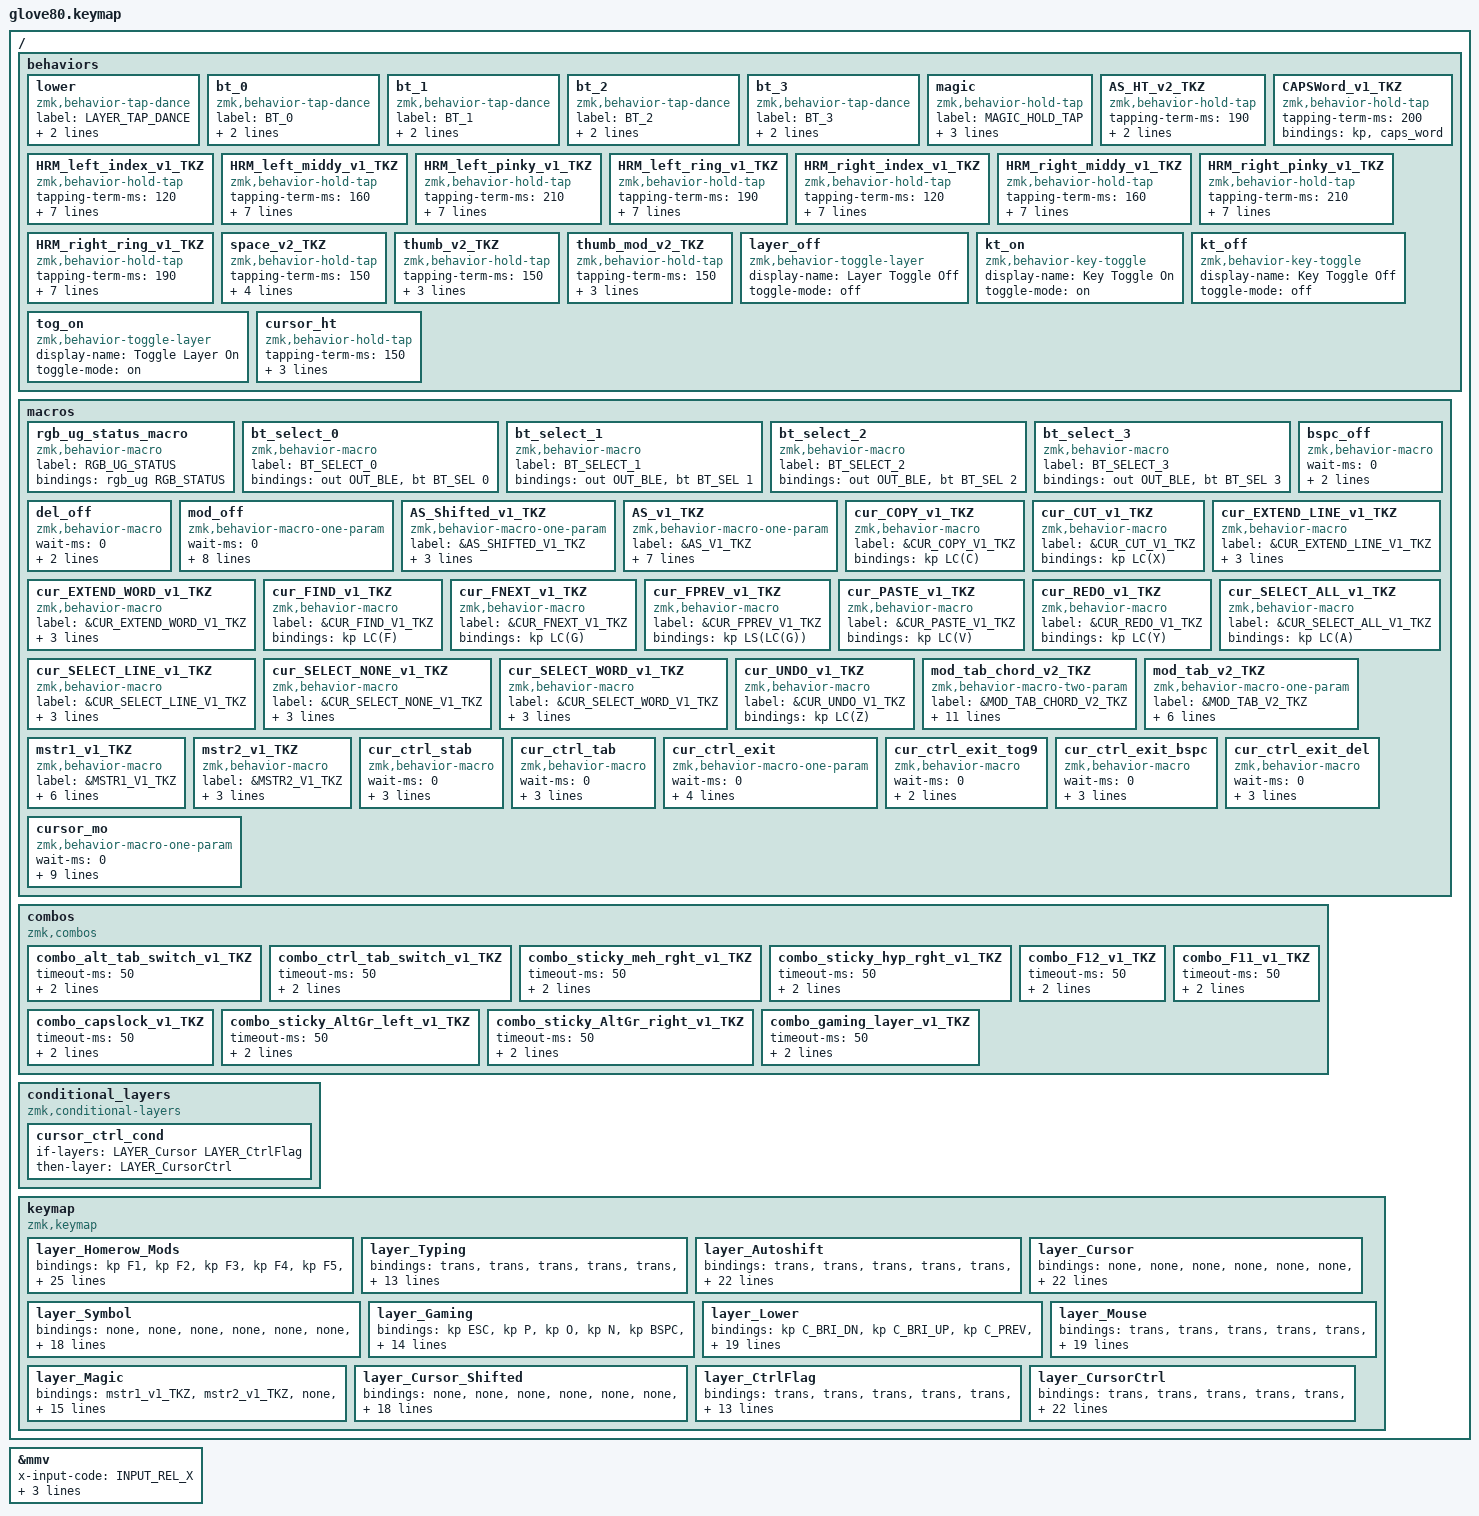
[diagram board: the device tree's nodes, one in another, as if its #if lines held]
/*
 * Copyright (c) 2020 The ZMK Contributors
 * Copyright (c) 2025 Innaworks Development Limited, trading as MoErgo
 *
 * SPDX-License-Identifier: MIT
 */


/* THIS FILE WAS GENERATED BY GLOVE80 LAYOUT EDITOR
 *
 * This file was generated automatically. You may or may not want to
 * edit it directly.
 */

#include <behaviors.dtsi>
/* Include all behavior includes needed */
#include <dt-bindings/zmk/outputs.h>
#include <dt-bindings/zmk/keys.h>
#include <dt-bindings/zmk/bt.h>
#include <dt-bindings/zmk/rgb.h>

/* On demand includes */
#define ZMK_POINTING_DEFAULT_MOVE_VAL 2100  // default: 600
#define ZMK_POINTING_DEFAULT_SCRL_VAL 20    // default: 10
#include <dt-bindings/zmk/pointing.h>

&mmv {
    x-input-code = <INPUT_REL_X>;
    y-input-code = <INPUT_REL_Y>;
    time-to-max-speed-ms = <700>;
    acceleration-exponent = <1>;
};

/* Automatically generated layer name #define */
#define LAYER_Homerow_Mods 0
#define LAYER_Typing 1
#define LAYER_Autoshift 2
#define LAYER_Cursor 3
#define LAYER_Symbol 4
#define LAYER_Gaming 5
#define LAYER_Lower 6
#define LAYER_Mouse 7
#define LAYER_Magic 8
#define LAYER_Cursor_Shifted 9
#define LAYER_CtrlFlag 10
#define LAYER_CursorCtrl 11

/* To deal with the situation where there is no Lower layer, to keep &lower happy */
#ifndef LAYER_Lower
#define LAYER_Lower 0
#endif

/* Custom Device-tree */


/* Input Listeners */


/* System behavior and Macros */
/ {
    behaviors {
        // For the "layer" key, it'd nice to be able to use it as either a shift or a toggle.
        // Configure it as a tap dance, so the first tap (or hold) is a &mo and the second tap is a &to
        lower: lower {
            compatible = "zmk,behavior-tap-dance";
            label = "LAYER_TAP_DANCE";
            #binding-cells = <0>;
            tapping-term-ms = <200>;
            bindings = <&mo LAYER_Lower>, <&to LAYER_Lower>;
        };
    };
};

/ {
    macros {
        rgb_ug_status_macro: rgb_ug_status_macro {
            label = "RGB_UG_STATUS";
            compatible = "zmk,behavior-macro";
            #binding-cells = <0>;
            bindings
                = <&rgb_ug RGB_STATUS>;
        };
    };
};


/ {
#ifdef BT_DISC_CMD
    behaviors {
        bt_0: bt_0 {
            compatible = "zmk,behavior-tap-dance";
            label = "BT_0";
            #binding-cells = <0>;
            tapping-term-ms = <200>;
            bindings = <&bt_select_0>, <&bt BT_DISC 0>;
        };
        bt_1: bt_1 {
            compatible = "zmk,behavior-tap-dance";
            label = "BT_1";
            #binding-cells = <0>;
            tapping-term-ms = <200>;
            bindings = <&bt_select_1>, <&bt BT_DISC 1>;
        };
        bt_2: bt_2 {
            compatible = "zmk,behavior-tap-dance";
            label = "BT_2";
            #binding-cells = <0>;
            tapping-term-ms = <200>;
            bindings = <&bt_select_2>, <&bt BT_DISC 2>;
        };
        bt_3: bt_3 {
            compatible = "zmk,behavior-tap-dance";
            label = "BT_3";
            #binding-cells = <0>;
            tapping-term-ms = <200>;
            bindings = <&bt_select_3>, <&bt BT_DISC 3>;
        };
    };
    macros {
        bt_select_0: bt_select_0 {
            label = "BT_SELECT_0";
            compatible = "zmk,behavior-macro";
            #binding-cells = <0>;
            bindings
                = <&out OUT_BLE>,
                  <&bt BT_SEL 0>;
        };
        bt_select_1: bt_select_1 {
            label = "BT_SELECT_1";
            compatible = "zmk,behavior-macro";
            #binding-cells = <0>;
            bindings
                = <&out OUT_BLE>,
                  <&bt BT_SEL 1>;
        };
        bt_select_2: bt_select_2 {
            label = "BT_SELECT_2";
            compatible = "zmk,behavior-macro";
            #binding-cells = <0>;
            bindings
                = <&out OUT_BLE>,
                  <&bt BT_SEL 2>;
        };
        bt_select_3: bt_select_3 {
            label = "BT_SELECT_3";
            compatible = "zmk,behavior-macro";
            #binding-cells = <0>;
            bindings
                = <&out OUT_BLE>,
                  <&bt BT_SEL 3>;
        };
    };
#else
    macros {
        bt_0: bt_0 {
            label = "BT_0";
            compatible = "zmk,behavior-macro";
            #binding-cells = <0>;
            bindings
                = <&out OUT_BLE>,
                  <&bt BT_SEL 0>;
        };
        bt_1: bt_1 {
            label = "BT_1";
            compatible = "zmk,behavior-macro";
            #binding-cells = <0>;
            bindings
                = <&out OUT_BLE>,
                  <&bt BT_SEL 1>;
        };
        bt_2: bt_2 {
            label = "BT_2";
            compatible = "zmk,behavior-macro";
            #binding-cells = <0>;
            bindings
                = <&out OUT_BLE>,
                  <&bt BT_SEL 2>;
        };
        bt_3: bt_3 {
            label = "BT_3";
            compatible = "zmk,behavior-macro";
            #binding-cells = <0>;
            bindings
                = <&out OUT_BLE>,
                  <&bt BT_SEL 3>;
        };
    };
#endif
};

/ {
    behaviors {
        magic: magic {
            compatible = "zmk,behavior-hold-tap";
            label = "MAGIC_HOLD_TAP";
            #binding-cells = <2>;
            flavor = "tap-preferred";
            tapping-term-ms = <200>;
            bindings = <&mo>, <&rgb_ug_status_macro>;
        };
    };
};

/* #define for key positions */
#define POS_LH_T1 52
#define POS_LH_T2 53
#define POS_LH_T3 54
#define POS_LH_T4 69
#define POS_LH_T5 70
#define POS_LH_T6 71
#define POS_LH_C1R2 15
#define POS_LH_C1R3 27
#define POS_LH_C1R4 39
#define POS_LH_C1R5 51
#define POS_LH_C2R1 4
#define POS_LH_C2R2 14
#define POS_LH_C2R3 26
#define POS_LH_C2R4 38
#define POS_LH_C2R5 50
#define POS_LH_C2R6 68
#define POS_LH_C3R1 3
#define POS_LH_C3R2 13
#define POS_LH_C3R3 25
#define POS_LH_C3R4 37
#define POS_LH_C3R5 49
#define POS_LH_C3R6 67
#define POS_LH_C4R1 2
#define POS_LH_C4R2 12
#define POS_LH_C4R3 24
#define POS_LH_C4R4 36
#define POS_LH_C4R5 48
#define POS_LH_C4R6 66
#define POS_LH_C5R1 1
#define POS_LH_C5R2 11
#define POS_LH_C5R3 23
#define POS_LH_C5R4 35
#define POS_LH_C5R5 47
#define POS_LH_C5R6 65
#define POS_LH_C6R1 0
#define POS_LH_C6R2 10
#define POS_LH_C6R3 22
#define POS_LH_C6R4 34
#define POS_LH_C6R5 46
#define POS_LH_C6R6 64
#define POS_RH_T1 57
#define POS_RH_T2 56
#define POS_RH_T3 55
#define POS_RH_T4 74
#define POS_RH_T5 73
#define POS_RH_T6 72
#define POS_RH_C1R2 16
#define POS_RH_C1R3 28
#define POS_RH_C1R4 40
#define POS_RH_C1R5 58
#define POS_RH_C2R1 5
#define POS_RH_C2R2 17
#define POS_RH_C2R3 29
#define POS_RH_C2R4 41
#define POS_RH_C2R5 59
#define POS_RH_C2R6 75
#define POS_RH_C3R1 6
#define POS_RH_C3R2 18
#define POS_RH_C3R3 30
#define POS_RH_C3R4 42
#define POS_RH_C3R5 60
#define POS_RH_C3R6 76
#define POS_RH_C4R1 7
#define POS_RH_C4R2 19
#define POS_RH_C4R3 31
#define POS_RH_C4R4 43
#define POS_RH_C4R5 61
#define POS_RH_C4R6 77
#define POS_RH_C5R1 8
#define POS_RH_C5R2 20
#define POS_RH_C5R3 32
#define POS_RH_C5R4 44
#define POS_RH_C5R5 62
#define POS_RH_C5R6 78
#define POS_RH_C6R1 9
#define POS_RH_C6R2 21
#define POS_RH_C6R3 33
#define POS_RH_C6R4 45
#define POS_RH_C6R5 63
#define POS_RH_C6R6 79

/* Custom Defined Behaviors */
/ {


};

/* Automatically generated macro definitions */
/ {
    macros {

        bspc_off: bspc_off {
            compatible = "zmk,behavior-macro";
            wait-ms = <0>;
            #binding-cells = <0>;
            bindings = <&layer_off LAYER_Cursor_Shifted>, <&kp BSPC>;
        };

        del_off: del_off {
            compatible = "zmk,behavior-macro";
            wait-ms = <0>;
            #binding-cells = <0>;
            bindings = <&layer_off LAYER_Cursor_Shifted>, <&kp DEL>;
        };

        mod_off: mod_off {
            compatible = "zmk,behavior-macro-one-param";
            wait-ms = <0>;
            tap-ms = <0>;
            #binding-cells = <1>;
            bindings = <&macro_tap &layer_off LAYER_Cursor_Shifted>,
            <&macro_param_1to1>,
            <&macro_press &mo MACRO_PLACEHOLDER>,
            <&macro_pause_for_release>,
            <&macro_param_1to1>,
            <&macro_release &mo MACRO_PLACEHOLDER>,
            <&macro_tap &layer_off LAYER_Cursor_Shifted>;
        };


        // AutoShift Helper- &AS main macro is chained to &AS_HT hold tap and &AS_Shifted macro - TailorKey
        AS_Shifted_v1_TKZ: AS_Shifted_v1_TKZ {
            label = "&AS_SHIFTED_V1_TKZ";
            compatible = "zmk,behavior-macro-one-param";
            #binding-cells = <1>;
            bindings = <&macro_press>
                , <&kp LSHFT>
                , <&macro_tap>
                , <&macro_param_1to1>
                , <&kp N1>
                , <&macro_release>
                , <&kp LSHFT>;
        };

        // AutoShift (Assign &AS to a Key) - &AS main macro is chained to &AS_HT hold tap and &AS_Shifted macro - TailorKey
        AS_v1_TKZ: AS_v1_TKZ {
            label = "&AS_V1_TKZ";
            compatible = "zmk,behavior-macro-one-param";
            #binding-cells = <1>;
            tap-ms = <10>;
            wait-ms = <10>;
            bindings = <&macro_press>
                , <&macro_param_1to1>
                , <&macro_param_1to2>
                , <&AS_HT_v2_TKZ A A>
                , <&macro_pause_for_release>
                , <&macro_release>
                , <&macro_param_1to1>
                , <&macro_param_1to2>
                , <&AS_HT_v2_TKZ A A>;
        };

        // Cursor Layer - Copy (Ctrl C) - TailorKey
        cur_COPY_v1_TKZ: cur_COPY_v1_TKZ {
            label = "&CUR_COPY_V1_TKZ";
            compatible = "zmk,behavior-macro";
            #binding-cells = <0>;
            bindings = <&kp LC(C)>;
        };

        // Cursor Layer - Cut (Ctrl X) - TailorKey
        cur_CUT_v1_TKZ: cur_CUT_v1_TKZ {
            label = "&CUR_CUT_V1_TKZ";
            compatible = "zmk,behavior-macro";
            #binding-cells = <0>;
            bindings = <&kp LC(X)>;
        };

        // Cursor Layer - Extent Line (seq) - TailorKey
        cur_EXTEND_LINE_v1_TKZ: cur_EXTEND_LINE_v1_TKZ {
            label = "&CUR_EXTEND_LINE_V1_TKZ";
            compatible = "zmk,behavior-macro";
            #binding-cells = <0>;
            tap-ms = <1>;
            wait-ms = <1>;
            bindings = <&kp LS(END)>;
        };

        // Cursor Layer - Extend Word (seq) - TailorKey
        cur_EXTEND_WORD_v1_TKZ: cur_EXTEND_WORD_v1_TKZ {
            label = "&CUR_EXTEND_WORD_V1_TKZ";
            compatible = "zmk,behavior-macro";
            #binding-cells = <0>;
            tap-ms = <1>;
            wait-ms = <1>;
            bindings = <&kp LC(LS(RIGHT))>;
        };

        // Cursor Layer - Find (Ctrl F) - TailorKey
        cur_FIND_v1_TKZ: cur_FIND_v1_TKZ {
            label = "&CUR_FIND_V1_TKZ";
            compatible = "zmk,behavior-macro";
            #binding-cells = <0>;
            bindings = <&kp LC(F)>;
        };

        // Cursor Layer - Find Next (Ctrl G) - TailorKey
        cur_FNEXT_v1_TKZ: cur_FNEXT_v1_TKZ {
            label = "&CUR_FNEXT_V1_TKZ";
            compatible = "zmk,behavior-macro";
            #binding-cells = <0>;
            bindings = <&kp LC(G)>;
        };

        // Cursor Layer - Find Prev (Ctrl Shift G) - TailorKey
        cur_FPREV_v1_TKZ: cur_FPREV_v1_TKZ {
            label = "&CUR_FPREV_V1_TKZ";
            compatible = "zmk,behavior-macro";
            #binding-cells = <0>;
            bindings = <&kp LS(LC(G))>;
        };

        // Cursor Layer - Paste (Ctrl V) - TailorKey
        cur_PASTE_v1_TKZ: cur_PASTE_v1_TKZ {
            label = "&CUR_PASTE_V1_TKZ";
            compatible = "zmk,behavior-macro";
            #binding-cells = <0>;
            bindings = <&kp LC(V)>;
        };

        // Cursor Layer - Redo (Ctrl Y) - TailorKey
        cur_REDO_v1_TKZ: cur_REDO_v1_TKZ {
            label = "&CUR_REDO_V1_TKZ";
            compatible = "zmk,behavior-macro";
            #binding-cells = <0>;
            bindings = <&kp LC(Y)>;
        };

        // Cursor Layer - Selest All (Ctrl A) - TailorKey
        cur_SELECT_ALL_v1_TKZ: cur_SELECT_ALL_v1_TKZ {
            label = "&CUR_SELECT_ALL_V1_TKZ";
            compatible = "zmk,behavior-macro";
            #binding-cells = <0>;
            bindings = <&kp LC(A)>;
        };

        // Cursor Layer - Select Line (seq) - TailorKey
        cur_SELECT_LINE_v1_TKZ: cur_SELECT_LINE_v1_TKZ {
            label = "&CUR_SELECT_LINE_V1_TKZ";
            compatible = "zmk,behavior-macro";
            #binding-cells = <0>;
            tap-ms = <1>;
            wait-ms = <1>;
            bindings = <&kp HOME>
                , <&kp LS(END)>;
        };

        // Cursor Layer - Select None (seq) - TailorKey
        cur_SELECT_NONE_v1_TKZ: cur_SELECT_NONE_v1_TKZ {
            label = "&CUR_SELECT_NONE_V1_TKZ";
            compatible = "zmk,behavior-macro";
            #binding-cells = <0>;
            tap-ms = <1>;
            wait-ms = <1>;
            bindings = <&kp DOWN>
                , <&kp UP>
                , <&kp RIGHT>
                , <&kp LEFT>;
        };

        // Cursor Layer - Select Word (seq) - TailorKey
        cur_SELECT_WORD_v1_TKZ: cur_SELECT_WORD_v1_TKZ {
            label = "&CUR_SELECT_WORD_V1_TKZ";
            compatible = "zmk,behavior-macro";
            #binding-cells = <0>;
            tap-ms = <1>;
            wait-ms = <1>;
            bindings = <&kp LC(LEFT)>
                , <&kp LC(LS(RIGHT))>;
        };

        // Cursor Layer - Undo (Ctrl Z) - TailorKey
        cur_UNDO_v1_TKZ: cur_UNDO_v1_TKZ {
            label = "&CUR_UNDO_V1_TKZ";
            compatible = "zmk,behavior-macro";
            #binding-cells = <0>;
            bindings = <&kp LC(Z)>;
        };

        // mod_tab_switcher_chord -  TailorKey
        mod_tab_chord_v2_TKZ: mod_tab_chord_v2_TKZ {
            label = "&MOD_TAB_CHORD_V2_TKZ";
            compatible = "zmk,behavior-macro-two-param";
            #binding-cells = <2>;
            tap-ms = <0>;
            wait-ms = <0>;
            bindings = <&macro_press>
                , <&macro_param_2to1>
                , <&mo MACRO_PLACEHOLDER>
                , <&macro_press>
                , <&macro_param_1to1>
                , <&mod_tab_v2_TKZ MACRO_PLACEHOLDER>
                , <&macro_pause_for_release>
                , <&macro_release>
                , <&macro_param_1to1>
                , <&mod_tab_v2_TKZ MACRO_PLACEHOLDER>
                , <&macro_release>
                , <&macro_param_2to1>
                , <&mo MACRO_PLACEHOLDER>;
        };

        // mod_tab_switcher - TailorKey
        //
        //
        mod_tab_v2_TKZ: mod_tab_v2_TKZ {
            label = "&MOD_TAB_V2_TKZ";
            compatible = "zmk,behavior-macro-one-param";
            #binding-cells = <1>;
            tap-ms = <0>;
            wait-ms = <0>;
            bindings = <&macro_press>
                , <&macro_param_1to1>
                , <&kp MACRO_PLACEHOLDER>
                , <&macro_tap>
                , <&kp TAB>
                , <&macro_pause_for_release>
                , <&macro_release>
                , <&macro_param_1to1>
                , <&kp MACRO_PLACEHOLDER>;
        };

        // macro string1 sample - Magic Layer F1 - Text output sample macro 1 "¡Hola!" - TailorKey
        mstr1_v1_TKZ: mstr1_v1_TKZ {
            label = "&MSTR1_V1_TKZ";
            compatible = "zmk,behavior-macro";
            #binding-cells = <0>;
            bindings = <&macro_press>
                , <&kp RALT>
                , <&macro_tap>
                , <&kp KP_N0>
                , <&kp KP_N1>
                , <&kp KP_N6>
                , <&kp KP_N1>
                , <&macro_release>
                , <&kp RALT>
                , <&macro_press>
                , <&kp LSHFT>
                , <&macro_tap>
                , <&kp H>
                , <&macro_release>
                , <&kp LSHFT>
                , <&macro_tap>
                , <&kp O>
                , <&kp L>
                , <&kp A>
                , <&kp EXCL>
                , <&kp SPACE>
                , <&kp RET>;
        };

        // macro string2 sample - Magic Layer F2 - Text output sample macro 2 "grammar check: <paste>" - TailorKey
        mstr2_v1_TKZ: mstr2_v1_TKZ {
            label = "&MSTR2_V1_TKZ";
            compatible = "zmk,behavior-macro";
            #binding-cells = <0>;
            bindings = <&macro_tap>
                , <&kp G>
                , <&kp R>
                , <&kp A>
                , <&kp M>
                , <&kp M>
                , <&kp A>
                , <&kp R>
                , <&kp SPACE>
                , <&kp C>
                , <&kp H>
                , <&kp E>
                , <&kp C>
                , <&kp K>
                , <&kp COLON>
                , <&kp LC(V)>
                , <&kp RET>;
        };

        cur_ctrl_stab: cur_ctrl_stab {
            compatible = "zmk,behavior-macro";
            wait-ms = <0>;
            tap-ms = <0>;
            #binding-cells = <0>;
            bindings = <&kt_on LCTRL>, <&tog_on LAYER_CtrlFlag>, <&kp LS(TAB)>;
        };

        cur_ctrl_tab: cur_ctrl_tab {
            compatible = "zmk,behavior-macro";
            wait-ms = <0>;
            tap-ms = <0>;
            #binding-cells = <0>;
            bindings = <&kt_on LCTRL>, <&tog_on LAYER_CtrlFlag>, <&kp TAB>;
        };

        cur_ctrl_exit: cur_ctrl_exit {
            compatible = "zmk,behavior-macro-one-param";
            wait-ms = <0>;
            tap-ms = <0>;
            #binding-cells = <1>;
            bindings = <&kt_off LCTRL>,
                       <&layer_off LAYER_CtrlFlag>,
                       <&macro_param_1to1>,
                       <&kp MACRO_PLACEHOLDER>;
        };

        cur_ctrl_exit_tog9: cur_ctrl_exit_tog9 {
            compatible = "zmk,behavior-macro";
            wait-ms = <0>;
            #binding-cells = <0>;
            bindings = <&kt_off LCTRL>, <&layer_off LAYER_CtrlFlag>, <&tog 9>;
        };

        cur_ctrl_exit_bspc: cur_ctrl_exit_bspc {
            compatible = "zmk,behavior-macro";
            wait-ms = <0>;
            #binding-cells = <0>;
            bindings = <&kt_off LCTRL>, <&layer_off LAYER_CtrlFlag>, <&layer_off LAYER_Cursor_Shifted>, <&kp BSPC>;
        };

        cur_ctrl_exit_del: cur_ctrl_exit_del {
            compatible = "zmk,behavior-macro";
            wait-ms = <0>;
            #binding-cells = <0>;
            bindings = <&kt_off LCTRL>, <&layer_off LAYER_CtrlFlag>, <&layer_off LAYER_Cursor_Shifted>, <&kp DEL>;
        };

        cursor_mo: cursor_mo {
            compatible = "zmk,behavior-macro-one-param";
            wait-ms = <0>;
            tap-ms = <0>;
            #binding-cells = <1>;
            bindings = <&macro_tap &layer_off LAYER_Cursor_Shifted>,
                       <&macro_param_1to1>,
                       <&macro_press &mo MACRO_PLACEHOLDER>,
                       <&macro_pause_for_release>,
                       <&kt_off LCTRL>,
                       <&layer_off LAYER_CtrlFlag>,
                       <&macro_param_1to1>,
                       <&macro_release &mo MACRO_PLACEHOLDER>,
                       <&macro_tap &layer_off LAYER_Cursor_Shifted>;
        };
    };
};

/* Automatically generated behavior definitions */
/ {
    behaviors {

        // AutoShift Helper - &AS main macro is chained to &AS_HT hold tap and &AS_Shifted macro. For faster typists, it is recommended to decrease the tapping-term-ms value. A suggested value is 135 ms.
        // More: https://github.com/nickcoutsos/keymap-editor/wiki/Autoshift-using-ZMK-behaviors
        AS_HT_v2_TKZ: AS_HT_v2_TKZ {
            compatible = "zmk,behavior-hold-tap";
            #binding-cells = <2>;
            tapping-term-ms = <190>;
            bindings = <&AS_Shifted_v1_TKZ>, <&kp>;
            flavor = "tap-preferred";
        };

        // Capsword helper - tap for caps_word - hold for key press
        CAPSWord_v1_TKZ: CAPSWord_v1_TKZ {
            compatible = "zmk,behavior-hold-tap";
            #binding-cells = <2>;
            tapping-term-ms = <200>;
            bindings = <&kp>, <&caps_word>;
        };

        // Homerow Mod for the left index finger - TailorKey.
        // For advanced tuning of HRM values, see: https://docs.google.com/spreadsheets/d/1ESgObQelyz4lnKlfwLYsmofLJulOMK5RdGBsopLe2o8
        HRM_left_index_v1_TKZ: HRM_left_index_v1_TKZ {
            compatible = "zmk,behavior-hold-tap";
            #binding-cells = <2>;
            tapping-term-ms = <120>;
            bindings = <&kp>, <&kp>;
            flavor = "tap-preferred";
            quick-tap-ms = <250>;
            require-prior-idle-ms = <50>;
            hold-trigger-key-positions = <57 56 55 72 73 74 5 6 7 8 16 17 18 19 20 28 29 30 31 32 40 41 42 43 44 58 59 60 61 62 75 76 77 78 9 21 33 45 63 79 52 53 54 70 71 69>;
            hold-trigger-on-release;
        };

        // Homerow Mod for the left middle finger - TailorKey
        HRM_left_middy_v1_TKZ: HRM_left_middy_v1_TKZ {
            compatible = "zmk,behavior-hold-tap";
            #binding-cells = <2>;
            tapping-term-ms = <160>;
            bindings = <&kp>, <&kp>;
            flavor = "tap-preferred";
            quick-tap-ms = <250>;
            require-prior-idle-ms = <100>;
            hold-trigger-key-positions = <57 56 55 72 73 74 5 6 7 8 16 17 18 19 20 28 29 30 31 32 40 41 42 43 44 58 59 60 61 62 75 76 77 78 9 21 33 45 63 79 52 53 54 69 70 71>;
            hold-trigger-on-release;
        };

        // Homerow Mod for the left pinky - TailorKey
        HRM_left_pinky_v1_TKZ: HRM_left_pinky_v1_TKZ {
            compatible = "zmk,behavior-hold-tap";
            #binding-cells = <2>;
            tapping-term-ms = <210>;
            bindings = <&kp>, <&kp>;
            flavor = "tap-preferred";
            quick-tap-ms = <250>;
            require-prior-idle-ms = <100>;
            hold-trigger-key-positions = <57 56 55 72 73 74 5 6 7 8 9 16 17 18 19 20 21 29 30 31 32 33 42 43 44 45 60 61 62 63 28 40 41 58 59 75 76 77 79 78 52 53 54 69 70 71>;
            hold-trigger-on-release;
        };

        // Homerow Mod for the left ring finger 1 - TailorKey
        HRM_left_ring_v1_TKZ: HRM_left_ring_v1_TKZ {
            compatible = "zmk,behavior-hold-tap";
            #binding-cells = <2>;
            tapping-term-ms = <190>;
            bindings = <&kp>, <&kp>;
            flavor = "tap-preferred";
            quick-tap-ms = <250>;
            require-prior-idle-ms = <100>;
            hold-trigger-key-positions = <57 56 55 72 73 74 5 6 7 8 16 17 18 19 20 28 29 30 31 32 40 41 42 43 44 58 59 60 61 62 75 76 77 78 9 21 33 45 63 79 52 53 54 69 70 71>;
            hold-trigger-on-release;
        };

        // Homerow Mod for the right index finger - TailorKey
        HRM_right_index_v1_TKZ: HRM_right_index_v1_TKZ {
            compatible = "zmk,behavior-hold-tap";
            #binding-cells = <2>;
            tapping-term-ms = <120>;
            bindings = <&kp>, <&kp>;
            flavor = "tap-preferred";
            quick-tap-ms = <250>;
            require-prior-idle-ms = <50>;
            hold-trigger-key-positions = <52 53 54 71 70 69 0 1 10 11 12 13 14 22 23 24 25 26 27 34 35 36 37 38 39 46 47 48 49 50 51 64 65 66 67 68 15 4 2 3 55 56 57 72 73 74>;
            hold-trigger-on-release;
        };

        // Homerow Mod for the right middle finger - TailorKey
        HRM_right_middy_v1_TKZ: HRM_right_middy_v1_TKZ {
            compatible = "zmk,behavior-hold-tap";
            #binding-cells = <2>;
            tapping-term-ms = <160>;
            bindings = <&kp>, <&kp>;
            flavor = "tap-preferred";
            quick-tap-ms = <250>;
            require-prior-idle-ms = <100>;
            hold-trigger-key-positions = <52 53 54 71 70 69 0 1 10 11 12 13 14 22 23 24 25 26 27 34 35 36 37 38 39 46 47 48 49 50 51 64 65 66 67 68 15 4 2 3 55 56 57 72 73 74>;
            hold-trigger-on-release;
        };

        // Homerow Mod for the right pinky - TailorKey
        HRM_right_pinky_v1_TKZ: HRM_right_pinky_v1_TKZ {
            compatible = "zmk,behavior-hold-tap";
            #binding-cells = <2>;
            tapping-term-ms = <210>;
            bindings = <&kp>, <&kp>;
            flavor = "tap-preferred";
            quick-tap-ms = <250>;
            require-prior-idle-ms = <100>;
            hold-trigger-key-positions = <52 53 54 71 70 69 0 1 10 11 12 13 14 22 23 24 25 26 27 34 35 36 37 38 39 46 47 48 49 50 51 64 65 66 67 68 15 4 2 3 55 56 57 72 73 74>;
            hold-trigger-on-release;
        };

        // Homerow Mod for the right ring 1 - TailorKey
        //
        HRM_right_ring_v1_TKZ: HRM_right_ring_v1_TKZ {
            compatible = "zmk,behavior-hold-tap";
            #binding-cells = <2>;
            tapping-term-ms = <190>;
            bindings = <&kp>, <&kp>;
            flavor = "tap-preferred";
            quick-tap-ms = <250>;
            require-prior-idle-ms = <100>;
            hold-trigger-key-positions = <52 53 54 71 70 69 0 1 10 11 12 13 14 22 23 24 25 26 27 34 35 36 37 38 39 46 47 48 49 50 51 64 65 66 67 68 15 4 2 3 55 56 57 72 73 74>;
            hold-trigger-on-release;
        };

        // space_layer_access - TailorKey
        space_v2_TKZ: space_v2_TKZ {
            compatible = "zmk,behavior-hold-tap";
            #binding-cells = <2>;
            tapping-term-ms = <150>;
            bindings = <&mo>, <&kp>;
            flavor = "balanced";
            quick-tap-ms = <100>;
            retro-tap;
        };

        // thumb_layer_access - TailorKey
        thumb_v2_TKZ: thumb_v2_TKZ {
            compatible = "zmk,behavior-hold-tap";
            #binding-cells = <2>;
            tapping-term-ms = <150>;
            bindings = <&mo>, <&kp>;
            flavor = "balanced";
            quick-tap-ms = <250>;
        };

        thumb_mod_v2_TKZ: thumb_mod_v2_TKZ {
            compatible = "zmk,behavior-hold-tap";
            #binding-cells = <2>;
            tapping-term-ms = <150>;
            bindings = <&kp>, <&kp>;
            flavor = "balanced";
            quick-tap-ms = <250>;
        };

        layer_off: layer_off {
            compatible = "zmk,behavior-toggle-layer";
            #binding-cells = <1>;
            display-name = "Layer Toggle Off";
            toggle-mode = "off";
        };

        kt_on: kt_on {
            compatible = "zmk,behavior-key-toggle";
            #binding-cells = <1>;
            display-name = "Key Toggle On";
            toggle-mode = "on";
        };

        kt_off: kt_off {
            compatible = "zmk,behavior-key-toggle";
            #binding-cells = <1>;
            display-name = "Key Toggle Off";
            toggle-mode = "off";
        };

        tog_on: tog_on {
            compatible = "zmk,behavior-toggle-layer";
            #binding-cells = <1>;
            display-name = "Toggle Layer On";
            toggle-mode = "on";
        };

        cursor_ht: cursor_ht {
            compatible = "zmk,behavior-hold-tap";
            #binding-cells = <2>;
            tapping-term-ms = <150>;
            bindings = <&cursor_mo>, <&kp>;
            flavor = "balanced";
            quick-tap-ms = <250>;
        };
    };
};

/* Automatically generated combos definitions */
/ {
      combos {
          compatible = "zmk,combos";
                  // Calls macro tab_switcher_gui_combo on Left T1/T4 - TailorKey
        combo_alt_tab_switch_v1_TKZ {
            timeout-ms = <50>;
            key-positions = <69 52>;
            bindings = <&mod_tab_chord_v2_TKZ LALT 5>;
        };

        // Calls macro tab_switcher_ctrl_combo on Left T4/T5 - TailorKey
        combo_ctrl_tab_switch_v1_TKZ {
            timeout-ms = <50>;
            key-positions = <69 70>;
            bindings = <&mod_tab_chord_v2_TKZ LCTRL 5>;
        };

        // sticky "meh" modifiers (Alt + Ctrl + Shift) - TailorKey
        combo_sticky_meh_rght_v1_TKZ {
            timeout-ms = <50>;
            key-positions = <73 74>;
            bindings = <&sk LA(LC(LSHFT))>;
        };

        // sticky "hyper" modifiers (Win + Alt + Ctrl + Shift) - TailorKey
        combo_sticky_hyp_rght_v1_TKZ {
            timeout-ms = <50>;
            key-positions = <74 57>;
            bindings = <&sk LG(LA(LC(LSHFT)))>;
        };

        // F12 on RH_C6 and RH_R1+R2 - TailorKey
        combo_F12_v1_TKZ {
            timeout-ms = <50>;
            key-positions = <9 21>;
            bindings = <&kp F12>;
        };

        // F11 on RH_C5 and RH_R1+R2 - TailorKey
        combo_F11_v1_TKZ {
            timeout-ms = <50>;
            key-positions = <8 20>;
            bindings = <&kp F11>;
        };

        // capslock when pressing both T1's - TailorKey
        combo_capslock_v1_TKZ {
            timeout-ms = <50>;
            key-positions = <52 57>;
            bindings = <&kp CAPS>;
        };

        // sticky "AltGr" left - TailorKey
        combo_sticky_AltGr_left_v1_TKZ {
            timeout-ms = <50>;
            key-positions = <70 53>;
            bindings = <&sk RALT>;
        };

        // sticky "AltGr" right - TailorKey
        combo_sticky_AltGr_right_v1_TKZ {
            timeout-ms = <50>;
            key-positions = <56 73>;
            bindings = <&sk RALT>;
        };

        // toggle gaming layer - TailorKey
        combo_gaming_layer_v1_TKZ {
            timeout-ms = <50>;
            key-positions = <54 71>;
            bindings = <&tog 5>;
        };
      };
    };

/* Automatically generated keymap */
/ {
    conditional_layers {
        compatible = "zmk,conditional-layers";
        cursor_ctrl_cond {
            if-layers = <LAYER_Cursor LAYER_CtrlFlag>;
            then-layer = <LAYER_CursorCtrl>;
        };
    };
};

/ {
    keymap {
        compatible = "zmk,keymap";


        layer_Homerow_Mods {
            bindings = <
               &kp F1                         &kp F2                         &kp F3                          &kp F4                          &kp F5                                                                                                                                                                                   &kp F6                           &kp F7                         &kp F8                             &kp F9    &kp F10
            &kp EQUAL                         &kp N1                         &kp N2                          &kp N3                          &kp N4  &kp N5                                                                                                                                          &kp N6                           &kp N7                           &kp N8                         &kp N9                             &kp N0  &kp MINUS
              &kp DEL                          &kp Q  &HRM_left_middy_v1_TKZ RALT W                           &kp E                           &kp R   &kp T                                                                                                                                           &kp Y                            &kp U                            &kp I  &HRM_right_ring_v1_TKZ RALT O                              &kp P   &kp BSLH
              &kp ESC  &HRM_left_pinky_v1_TKZ LGUI A   &HRM_left_ring_v1_TKZ LALT S  &HRM_left_middy_v1_TKZ LCTRL D  &HRM_left_index_v1_TKZ LSHFT F   &kp G                                                                                                                                           &kp H  &HRM_right_index_v1_TKZ RSHFT J  &HRM_right_middy_v1_TKZ RCTRL K  &HRM_right_ring_v1_TKZ LALT L  &HRM_right_pinky_v1_TKZ LGUI SEMI    &kp SQT
            &kp GRAVE                          &kp Z                          &kp X                           &kp C                           &kp V   &kp B  &CAPSWord_v1_TKZ LSHFT MACRO_PLACEHOLDER  &kp LCTRL  &kp LGUI    &lower            &kp RCTRL  &CAPSWord_v1_TKZ RSHFT MACRO_PLACEHOLDER   &kp N                            &kp M                        &kp COMMA                        &kp DOT                           &kp FSLH  &kp UP
 &magic LAYER_Magic 0                       &kp LEFT                        &kp RIGHT                        &kp HOME                       &kp END                              &cursor_ht 3 BSPC    &kp TAB  &thumb_mod_v2_TKZ RALT SPACE  &kp LALT  &thumb_v2_TKZ 7 RET                     &space_v2_TKZ 4 SPACE                                   &kp PG_DN                         &kp PG_UP                       &kp LBKT                           &kp RBKT  &kp DOWN
            >;
        };

        layer_Typing {
            bindings = <
               &trans  &trans  &trans  &trans  &trans                                                                  &trans     &trans    &trans    &trans     &trans
            &kp EQUAL  &kp N1  &kp N2  &kp N3  &kp N4  &kp N5                                                  &kp N6  &kp N7     &kp N8    &kp N9    &kp N0  &kp MINUS
               &trans   &kp Q   &kp W   &kp E   &kp R   &kp T                                                   &kp Y   &kp U      &kp I     &kp O     &kp P   &kp BSLH
               &trans   &kp A   &kp S   &kp D   &kp F   &kp G                                                   &kp H   &kp J      &kp K     &kp L  &kp SEMI    &kp SQT
            &kp GRAVE   &kp Z   &kp X   &kp C   &kp V   &kp B  &trans  &trans  &trans  &trans  &trans  &trans   &kp N   &kp M  &kp COMMA   &kp DOT  &kp FSLH     &trans
 &magic LAYER_Magic 0  &trans  &trans  &trans  &trans          &trans  &trans  &trans  &trans  &trans  &trans          &trans     &trans  &kp LBKT  &kp RBKT     &trans
            >;
        };

        layer_Autoshift {
            bindings = <
               &trans         &trans         &trans         &trans         &trans                                                                                       &trans            &trans           &trans           &trans            &trans
     &AS_v1_TKZ EQUAL  &AS_v1_TKZ N1  &AS_v1_TKZ N2  &AS_v1_TKZ N3  &AS_v1_TKZ N4  &AS_v1_TKZ N5                                                  &AS_v1_TKZ N6  &AS_v1_TKZ N7     &AS_v1_TKZ N8    &AS_v1_TKZ N9    &AS_v1_TKZ N0  &AS_v1_TKZ MINUS
               &trans   &AS_v1_TKZ Q   &AS_v1_TKZ W   &AS_v1_TKZ E   &AS_v1_TKZ R   &AS_v1_TKZ T                                                   &AS_v1_TKZ Y   &AS_v1_TKZ U      &AS_v1_TKZ I     &AS_v1_TKZ O     &AS_v1_TKZ P   &AS_v1_TKZ BSLH
               &trans   &AS_v1_TKZ A   &AS_v1_TKZ S   &AS_v1_TKZ D   &AS_v1_TKZ F   &AS_v1_TKZ G                                                   &AS_v1_TKZ H   &AS_v1_TKZ J      &AS_v1_TKZ K     &AS_v1_TKZ L  &AS_v1_TKZ SEMI    &AS_v1_TKZ SQT
     &AS_v1_TKZ GRAVE   &AS_v1_TKZ Z   &AS_v1_TKZ X   &AS_v1_TKZ C   &AS_v1_TKZ V   &AS_v1_TKZ B  &trans  &trans  &trans  &trans  &trans  &trans   &AS_v1_TKZ N   &AS_v1_TKZ M  &AS_v1_TKZ COMMA   &AS_v1_TKZ DOT  &AS_v1_TKZ FSLH            &trans
 &magic LAYER_Magic 0         &trans         &trans         &trans         &trans                 &trans  &trans  &trans  &trans  &trans  &trans                        &trans            &trans  &AS_v1_TKZ LBKT  &AS_v1_TKZ RBKT            &trans
            >;
        };

        layer_Cursor {
            bindings = <
                &none                   &none                    &none                    &none              &none                                                                                                                          &none          &none         &none        &none   &none
              &kp ESC                 &kp RET                &kp SPACE                  &kp TAB            &kp DEL            &kp INS                                                                                     &kp PSCRN     &trans  &trans         &trans       &trans  &trans
            &kp LC(E)               &sk LSHFT         &cur_ctrl_stab           &cur_ctrl_tab              &kp BSPC    &cur_CUT_v1_TKZ                                                                                        &trans     &kp HOME       &kp END     &kp LS(TAB)        &kp TAB       &trans
            &kp LC(L)                &kp LGUI                 &kp LALT                &kp LCTRL          &kp LSHFT   &cur_COPY_v1_TKZ                                                                                      &kp LEFT      &kp DOWN         &kp UP      &kp RIGHT       &kp BSPC  &tog 9
            &kp LC(J)  &cur_SELECT_ALL_v1_TKZ  &cur_SELECT_LINE_v1_TKZ  &cur_SELECT_WORD_v1_TKZ   &cur_FIND_v1_TKZ  &cur_PASTE_v1_TKZ  &mod_tab_v2_TKZ LALT   &mod_tab_v2_TKZ LGUI  &kp PSCRN  &trans    &trans   &trans     &trans  &kp LC(LEFT)  &kp LC(RIGHT)  &kp LC(BSPC)  &kp LC(DEL)  &trans
 &magic LAYER_Magic 0       &cur_FPREV_v1_TKZ  &cur_EXTEND_LINE_v1_TKZ  &cur_EXTEND_WORD_v1_TKZ  &cur_FNEXT_v1_TKZ                                    &none  &mod_tab_v2_TKZ LCTRL  &kp LG(D)  &trans  &bspc_off  &del_off                   &trans         &trans        &trans       &trans  &trans
            >;
        };

        layer_Symbol {
            bindings = <
     &none      &none      &none      &none     &none                                                                                           &none             &none                    &none                    &none                   &none
 &kp GRAVE   &kp LBKT   &kp LPAR   &kp RPAR  &kp RBKT    &kp DOT                                                              &none         &sk RSHFT         &sk RCTRL                 &sk RALT                 &sk RGUI                   &none
  &kp EXCL  &kp AMPS  &kp LBKT   &kp RBKT   &kp PLUS  &kp PRCNT  &kp LT                                                            &kp GT           &kp TILDE            &kp DLLR                 &kp RIGHT                &kp END
  &kp HASH  &kp LBRC  &kp LPAR  &kp RPAR  &kp RBRC  &kp EQUAL   &kp HASH           &kp MINUS           &kp UNDER               &kp STAR                  &kp GRAVE                &kp HOME
 &kp TILDE     &kp PIPE   &kp SQT  &kp DQT    &kp AT   &kp EXCL   &kp BSLH    &kp DOT  &kp STAR   &none   &none   &none    &kp CARET           &kp EXCL       &kp LS(TAB)  &cur_SELECT_WORD_v1_TKZ  &cur_SELECT_LINE_v1_TKZ  &cur_SELECT_ALL_v1_TKZ
     &none   &kp AMPS    &kp SQT    &kp DQT  &kp PLUS             &kp PRCNT  &kp COLON    &kp AT   &none   &none   &none             &cur_UNDO_v1_TKZ  &cur_REDO_v1_TKZ  &cur_EXTEND_WORD_v1_TKZ  &cur_EXTEND_LINE_v1_TKZ                   &none
            >;
        };

        layer_Gaming {
            bindings = <
 &kp ESC      &kp P   &kp O   &kp N  &kp BSPC                                                                                   &kp F1     &kp F2    &kp F3     &kp F4     &kp F5
   &kp M     &kp N6  &kp N7  &kp N8    &kp N9  &kp N0                                                                &kp F6     &kp F7     &kp F8    &kp F9    &kp F10    &kp F11
   &kp I     &kp N1  &kp N2  &kp N3    &kp N4  &kp N5                                                                 &kp Y      &kp U      &kp I     &kp O      &kp P    &kp F12
   &kp T    &kp TAB   &kp Q   &kp W     &kp E   &kp R                                                                 &kp H      &kp J      &kp K     &kp L   &kp SEMI    &kp SQT
   &kp G  &kp LSHFT   &kp A   &kp S     &kp D   &kp F  &kp LSHFT   &kp LALT  &kp RET   &kp ESC    &kp UP    &kp RET   &kp N      &kp M  &kp COMMA   &kp DOT   &kp FSLH   &kp BSLH
   &kp B  &kp LCTRL   &kp Z   &kp X     &kp C          &kp SPACE  &kp LCTRL    &kp V  &kp LEFT  &kp DOWN  &kp RIGHT          &kp MINUS   &kp LBKT  &kp RBKT  &kp EQUAL  &kp GRAVE
            >;
        };

        layer_Lower {
            bindings = <
         &kp C_BRI_DN  &kp C_BRI_UP      &kp C_PREV      &kp C_NEXT         &kp C_PP                                                                                    &kp C_MUTE  &kp C_VOL_DN  &kp C_VOL_UP            &none  &kp PAUSE_BREAK
               &trans         &none           &none           &none            &none   &kp HOME                                                   &kp LEFT_PARENTHESIS  &kp KP_NUM     &kp EQUAL  &kp KP_SLASH  &kp KP_MULTIPLY  &kp PRINTSCREEN
               &trans         &none           &none    &kp UP_ARROW            &none    &kp END                                                  &kp RIGHT_PARENTHESIS   &kp KP_N7     &kp KP_N8     &kp KP_N9     &kp KP_MINUS   &kp SCROLLLOCK
               &trans         &none  &kp LEFT_ARROW  &kp DOWN_ARROW  &kp RIGHT_ARROW  &kp PG_UP                                                            &kp PERCENT   &kp KP_N4     &kp KP_N5     &kp KP_N6      &kp KP_PLUS            &none
               &trans     &kp K_APP           &none         &kp F11          &kp F12  &kp PG_DN  &trans  &trans   &to 0  &trans  &trans  &trans              &kp COMMA   &kp KP_N1     &kp KP_N2     &kp KP_N3     &kp KP_ENTER           &trans
 &magic LAYER_Magic 0      &kp CAPS         &kp INS         &kp F11          &kp F12             &trans  &trans  &trans  &trans  &trans  &trans                          &kp KP_N0     &kp KP_N0    &kp KP_DOT     &kp KP_ENTER           &trans
            >;
        };

        layer_Mouse {
            bindings = <
 &trans          &trans          &trans          &trans           &trans                                                                                                        &trans        &trans          &trans           &trans    &trans
 &trans          &trans          &trans          &trans           &trans             &trans                                                                     &trans       &sk LSHFT     &sk LCTRL        &sk LALT         &sk LGUI    &trans
 &trans          &trans  &msc SCRL_LEFT    &mmv MOVE_UP  &msc SCRL_RIGHT       &msc SCRL_UP                                                            &cur_CUT_v1_TKZ  &msc SCRL_DOWN  &msc SCRL_UP           &none            &none    &trans
 &trans    &msc SCRL_UP  &mmv MOVE_LEFT  &mmv MOVE_DOWN  &mmv MOVE_RIGHT     &msc SCRL_DOWN                                                           &cur_COPY_v1_TKZ       &mkp LCLK     &mkp RCLK       &mkp MCLK        &kp K_APP    &trans
 &trans  &msc SCRL_DOWN           &none           &none            &none  &cur_PASTE_v1_TKZ  &mkp MCLK  &kp K_APP  &mkp MB5  &trans  &trans  &trans  &cur_PASTE_v1_TKZ  &mmv MOVE_LEFT  &mmv MOVE_UP  &mmv MOVE_DOWN  &mmv MOVE_RIGHT    &trans
 &trans          &trans          &trans          &trans           &trans                     &mkp LCLK  &mkp RCLK  &mkp MB4  &trans  &trans  &trans                          &mkp LCLK     &mkp RCLK       &mkp MCLK         &mkp MB4  &mkp MB5
            >;
        };

        layer_Magic {
            bindings = <
 &mstr1_v1_TKZ    &mstr2_v1_TKZ            &none            &none            &none                                                                                  &none   &none   &none  &bt BT_CLR  &bt BT_CLR_ALL
         &to 0            &to 1            &to 2            &none            &none            &none                                                         &none   &none   &none   &none       &none           &none
         &none  &rgb_ug RGB_SPI  &rgb_ug RGB_SAI  &rgb_ug RGB_HUI  &rgb_ug RGB_BRI  &rgb_ug RGB_TOG                                                         &none   &none   &none   &none       &none           &none
   &bootloader  &rgb_ug RGB_SPD  &rgb_ug RGB_SAD  &rgb_ug RGB_HUD  &rgb_ug RGB_BRD  &rgb_ug RGB_EFF                                                         &none   &none   &none   &none       &none     &bootloader
    &sys_reset            &none            &none            &none            &none            &none   &bt_2   &bt_3         &none   &none   &none   &none   &none   &none   &none   &none       &none      &sys_reset
         &none            &none            &none            &none            &none                    &bt_0   &bt_1  &out OUT_USB   &none   &none   &none           &none   &none   &none       &none           &none
            >;
        };

        layer_Cursor_Shifted {
            bindings = <
                &none                   &none                    &none                    &none              &none                                                                                   &none              &none          &none        &none   &none
              &kp ESC                 &kp RET                &kp SPACE                   &trans             &trans  &trans                                                     &kp PSCRN      &kp LS(HOME)        &kp LS(END)         &trans       &trans  &trans
            &kp LC(E)                  &trans                   &trans                   &trans             &trans  &trans                                                        &trans         &kp PG_DN          &kp PG_UP         &trans       &trans  &trans
            &kp LC(L)                &kp LGUI                 &kp LALT                &kp LCTRL          &kp LSHFT  &trans                                                  &kp LS(LEFT)      &kp LS(DOWN)         &kp LS(UP)  &kp LS(RIGHT)       &trans  &trans
            &kp LC(J)  &cur_SELECT_ALL_v1_TKZ  &cur_SELECT_LINE_v1_TKZ                   &trans             &trans  &trans  &trans  &trans  &trans  &trans  &trans  &trans        &trans  &kp LC(LS(LEFT))  &kp LC(LS(RIGHT))   &kp LS(BSPC)  &kp LS(DEL)  &trans
 &magic LAYER_Magic 0       &cur_FPREV_v1_TKZ  &cur_EXTEND_LINE_v1_TKZ  &cur_EXTEND_WORD_v1_TKZ  &cur_FNEXT_v1_TKZ           &none  &trans  &trans  &trans  &trans  &trans                          &trans             &trans         &trans       &trans  &trans
            >;
        };

        layer_CtrlFlag {
            bindings = <
                &trans &trans &trans &trans &trans &trans &trans &trans &trans &trans
                &trans &trans &trans &trans &trans &trans &trans &trans &trans &trans &trans &trans
                &trans &trans &trans &trans &trans &trans &trans &trans &trans &trans &trans &trans
                &trans &trans &trans &trans &trans &trans &trans &trans &trans &trans &trans &trans
                &trans &trans &trans &trans &trans &trans &trans &trans &trans &trans &trans &trans &trans &trans &trans &trans &trans &trans
                &trans &trans &trans &trans &trans &trans &trans &trans &trans &trans &trans &trans &trans &trans &trans &trans
            >;
        };

        layer_CursorCtrl {
            bindings = <
                &trans                  &trans                   &trans                   &trans             &trans                                                                                                                                               &trans                   &trans                   &trans                    &trans   &trans
                &trans                  &trans                   &trans                   &trans             &trans             &trans                                                                                    &cur_ctrl_exit PSCRN   &cur_ctrl_exit HOME   &cur_ctrl_exit END               &trans   &trans   &trans
                &trans                  &trans                   &kp LS(TAB)              &kp TAB            &trans             &trans                                                                                               &trans  &cur_ctrl_exit PG_DN   &cur_ctrl_exit PG_UP   &cur_ctrl_exit LS(TAB)   &cur_ctrl_exit TAB   &trans
                &trans                  &trans                   &trans                   &trans             &trans             &trans                                                                                 &cur_ctrl_exit LEFT   &cur_ctrl_exit DOWN     &cur_ctrl_exit UP   &cur_ctrl_exit RIGHT   &cur_ctrl_exit BSPC   &cur_ctrl_exit_tog9
                &trans                  &trans                   &trans                   &trans             &trans             &trans             &trans             &trans   &trans   &trans   &trans   &trans             &trans   &cur_ctrl_exit LC(LEFT)   &cur_ctrl_exit LC(RIGHT)   &cur_ctrl_exit LC(BSPC)   &cur_ctrl_exit LC(DEL)   &trans
                &trans                  &trans                   &trans                   &trans             &trans                                                    &trans             &trans   &trans   &trans   &cur_ctrl_exit_bspc   &cur_ctrl_exit_del                   &trans                   &trans                    &trans   &trans   &trans
            >;
        };

    };
};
